# SN32F400 register map
Vendor: SONiX Technology Co., Ltd.; Series: SN32F400; File version: 1.1
CPU: CM0 r0p0, little endian, no MPU, no FPU, 2 interrupt priority bits
Registers are 32-bit, read-write, reset 0x0 unless marked. A register's access mark holds for its fields unless they carry their own. Offsets are from the block's base; [hi:lo] are bit positions; {n}, {i} and the like mark numbered series.

## SN_I2C0 — I2C0
Base 0x40018000
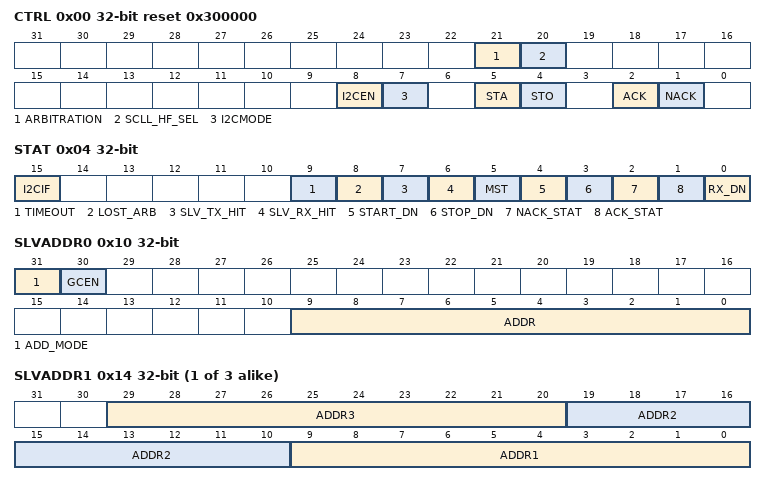
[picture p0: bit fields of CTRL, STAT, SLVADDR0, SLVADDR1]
0x00 CTRL reset 0x300000 — Offset:0x00 I2Cn Control register
  [21] ARBITRATION — Master Arbitration Enable bit
    0=Disable Arbitration; 1=Enable Arbitration
  [20] SCLL_HF_SEL — I2C TX_BIT changing timing bit
    0=SCL negative edge (Change at SCL negative edge); 1=Half of SCL low edge (Change at half of SCL low edge)
  [8] I2CEN — I2Cn interface enable
    0=Disable I2C; 1=Enable I2C
  [7] I2CMODE
    0=Standard/Fast mode
  [5] STA — START assert flag
    0=None (No START condition or Repeated START condition will be generated); 1=Assert (Enter master mode and transmit a START or Repeated START condition)
  [4] STO — STOP assert flag
    0=Idle (STOP condition idle); 1=Assert (Transmit a STOP condition in master mode, or recover from an error condition in slave mode)
  [2] ACK — ACK assert flag
    0=None (Master: No action/Slave: Assert NACK after receiving); 1=Assert ACK during the acknowledge clock pulse on SCLn
  [1] NACK — NACK assert flag
    0=None (No action); 1=Assert NACK during the acknowledge clock pulse on SCLn
0x04 STAT — Offset:0x04 I2Cn Status register
  [15] I2CIF — I2C interrupt flag
    0=None (I2C status doesn't change); 1=Change (I2C status changes)
  [9] TIMEOUT ro — Time-out status
    0=No (No timeout); 1=TO (Timeout)
  [8] LOST_ARB ro — Lost arbitration status
    0=None (Not lost arbitration); 1=Lost arbitration
  [7] SLV_TX_HIT ro — Slave TX address hit flag
    0=None (No matched slave address); 1=Hit (Slave address hit, and is called for TX)
  [6] SLV_RX_HIT ro — Slave RX address hit flag
    0=None (No matched slave address); 1=Hit (Slave address hit, and is called for RX)
  [5] MST ro — I2C master/slave status
    0=Slave (Act as Slave); 1=Master (Act as Master)
  [4] START_DN ro — START done status
    0=No (No START condition); 1=Assert (Transmit or receive a START condition)
  [3] STOP_DN ro — STOP done status
    0=No (No STOP condition); 1=Done (Transmit or receive a STOP condition)
  [2] NACK_STAT ro — NACK done status
    0=No (No NACK received); 1=Done (Receive a NACK)
  [1] ACK_STAT ro — ACK done status
    0=No (No ACK received); 1=Done (Receive an ACK)
  [0] RX_DN ro — RX done status
    0=Not done (No RX with ACK/NACK transfer); 1=Done (8-bit RX with ACK/NACK transfer)
0x08 TXDATA — Offset:0x08 I2Cn TX Data register
  [7:0] Data — TX Data
0x0C RXDATA ro — Offset:0x0C I2Cn RX Data register
  [7:0] Data — RX Data received when RX_DN=1
0x10 SLVADDR0 — Offset:0x10 I2Cn Slave Address 0 register
  [31] ADD_MODE — Slave address mode
    0=7-bit slave address mode; 1=10-bit slave address mode
  [30] GCEN — General call address enable
    0=Disable general call address; 1=Enable general call address (0x0)
  [9:0] ADDR — I2Cn slave address 0
{0x10+4i} SLVADDR{i} (i=1..3) — Offset:{0x10+4i} I2Cn Slave Address {i} register
  [29:20] ADDR{3i} — I2Cn slave address {3i}
  [19:10] ADDR{3i-1} — I2Cn slave address {3i-1}
  [9:0] ADDR{3i-2} — I2Cn slave address {3i-2}
0x20 SCLHT reset 0x4 — Offset:0x20 I2Cn SCL High Time register
  [15:0] SCLH — SCLn High period time=(SCLHT+1)*I2Cn_PCLK cycle
0x24 SCLLT reset 0x4 — Offset:0x24 I2Cn SCL Low Time register
  [15:0] SCLL — SCLn Low period time=(SCLLT+1)*I2Cn_PCLK cycle
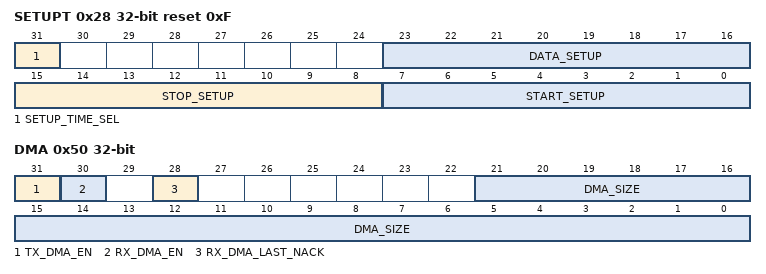
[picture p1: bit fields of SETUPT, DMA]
0x28 SETUPT reset 0xF — Offset:0x28 I2Cn Setup Time register
  [31] SETUP_TIME_SEL — Setup unit time selection
    0=PCLK (SETUP unit time = PCLK); 1=User defined (SETUP unit time = User defined (ns))
  [23:16] DATA_SETUP — DATA setup time = (DATA_SETUP +1) * I2Cn_PCLK cycle
  [15:8] STOP_SETUP — STOP setup time = (STOP_SETUP +1) * I2Cn_PCLK cycle
  [7:0] START_SETUP — START setup time = (START_SETUP +1) * I2Cn_PCLK cycle
0x2C TOCTRL — Offset:0x2C I2Cn Timeout Control register
  [15:0] TO — Timeout period time = TO*32*I2Cn_PCLK cycle
0x50 DMA — Offset:0x50 I2Cn DMA mode register
  [31] TX_DMA_EN — TX DMA mode enable
    0=Disable TX DMA mode; 1=Enable TX DMA mode
  [30] RX_DMA_EN — RX DMA mode enable
    0=Disable RX DMA mode; 1=Enable RX DMA mode
  [28] RX_DMA_LAST_NACK — I2C issues NACK/ACK for last data in RX DMA mode
    0=ACK (I2C issue ACK for last data in RX DMA mode); 1=NACK (I2C issue NACK for last data in RX DMA mode)
  [21:0] DMA_SIZE — Total DMA transfer size (in byte)
